# MIMXRT1015 register map
Vendor: nxp.com; File version: 1.0
CPU: CM7 r0p1, little endian, MPU, FPU, VTOR, 4 interrupt priority bits
Registers are 32-bit, read-write, reset 0x0 unless marked. A register's access mark holds for its fields unless they carry their own. Offsets are from the block's base; [hi:lo] are bit positions.

## IOMUXC (part 1 of 2)
Base 0x401F8000; register names take the prefix IOMUXC_
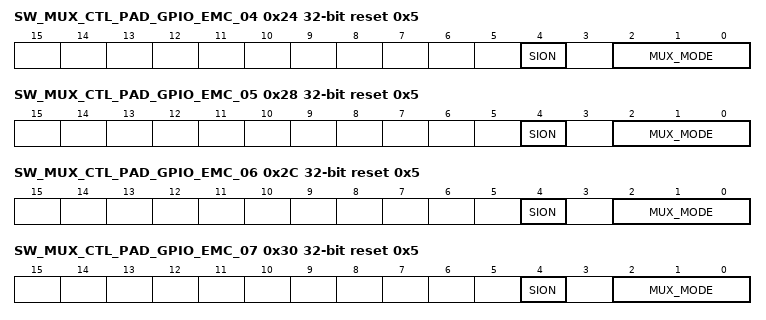
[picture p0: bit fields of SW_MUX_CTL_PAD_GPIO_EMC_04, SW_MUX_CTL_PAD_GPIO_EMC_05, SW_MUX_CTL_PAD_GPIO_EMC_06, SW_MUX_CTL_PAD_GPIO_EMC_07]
0x24 SW_MUX_CTL_PAD_GPIO_EMC_04 reset 0x5 — SW_MUX_CTL_PAD_GPIO_EMC_04 SW MUX Control Register
  [4] SION — Software Input On Field.
    0=DISABLED (Input Path is determined by functionality); 1=ENABLED (Force input path of pad GPIO_EMC_04)
  [2:0] MUX_MODE — MUX Mode Select Field.
    1=ALT1 (Select mux mode: ALT1 mux port: XBAR1_XBAR_INOUT04 of instance: xbar1); 2=ALT2 (Select mux mode: ALT2 mux port: SPDIF_OUT of instance: spdif); 3=ALT3 (Select mux mode: ALT3 mux port: SAI2_TX_BCLK of instance: sai2); 4=ALT4 (Select mux mode: ALT4 mux port: FLEXIO1_FLEXIO16 of instance: flexio1); 5=ALT5 (Select mux mode: ALT5 mux port: GPIO2_IO04 of instance: gpio2); 7=ALT7 (Select mux mode: ALT7 mux port: SJC_JTAG_ACT of instance: sjc)
0x28 SW_MUX_CTL_PAD_GPIO_EMC_05 reset 0x5 — SW_MUX_CTL_PAD_GPIO_EMC_05 SW MUX Control Register
  [4] SION — Software Input On Field.
    0=DISABLED (Input Path is determined by functionality); 1=ENABLED (Force input path of pad GPIO_EMC_05)
  [2:0] MUX_MODE — MUX Mode Select Field.
    1=ALT1 (Select mux mode: ALT1 mux port: XBAR1_XBAR_INOUT05 of instance: xbar1); 2=ALT2 (Select mux mode: ALT2 mux port: SPDIF_IN of instance: spdif); 3=ALT3 (Select mux mode: ALT3 mux port: SAI2_TX_SYNC of instance: sai2); 4=ALT4 (Select mux mode: ALT4 mux port: FLEXIO1_FLEXIO17 of instance: flexio1); 5=ALT5 (Select mux mode: ALT5 mux port: GPIO2_IO05 of instance: gpio2); 7=ALT7 (Select mux mode: ALT7 mux port: SJC_DE_B of instance: sjc)
0x2C SW_MUX_CTL_PAD_GPIO_EMC_06 reset 0x5 — SW_MUX_CTL_PAD_GPIO_EMC_06 SW MUX Control Register
  [4] SION — Software Input On Field.
    0=DISABLED (Input Path is determined by functionality); 1=ENABLED (Force input path of pad GPIO_EMC_06)
  [2:0] MUX_MODE — MUX Mode Select Field.
    1=ALT1 (Select mux mode: ALT1 mux port: XBAR1_XBAR_INOUT06 of instance: xbar1); 2=ALT2 (Select mux mode: ALT2 mux port: LPUART3_TX of instance: lpuart3); 3=ALT3 (Select mux mode: ALT3 mux port: SAI2_TX_DATA of instance: sai2); 4=ALT4 (Select mux mode: ALT4 mux port: FLEXIO1_FLEXIO18 of instance: flexio1); 5=ALT5 (Select mux mode: ALT5 mux port: GPIO2_IO06 of instance: gpio2)
0x30 SW_MUX_CTL_PAD_GPIO_EMC_07 reset 0x5 — SW_MUX_CTL_PAD_GPIO_EMC_07 SW MUX Control Register
  [4] SION — Software Input On Field.
    0=DISABLED (Input Path is determined by functionality); 1=ENABLED (Force input path of pad GPIO_EMC_07)
  [2:0] MUX_MODE — MUX Mode Select Field.
    1=ALT1 (Select mux mode: ALT1 mux port: XBAR1_XBAR_INOUT07 of instance: xbar1); 2=ALT2 (Select mux mode: ALT2 mux port: LPUART3_RX of instance: lpuart3); 3=ALT3 (Select mux mode: ALT3 mux port: SAI2_RX_SYNC of instance: sai2); 4=ALT4 (Select mux mode: ALT4 mux port: FLEXIO1_FLEXIO19 of instance: flexio1); 5=ALT5 (Select mux mode: ALT5 mux port: GPIO2_IO07 of instance: gpio2)
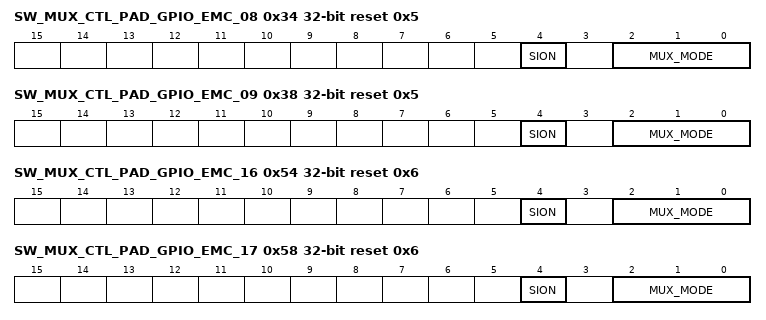
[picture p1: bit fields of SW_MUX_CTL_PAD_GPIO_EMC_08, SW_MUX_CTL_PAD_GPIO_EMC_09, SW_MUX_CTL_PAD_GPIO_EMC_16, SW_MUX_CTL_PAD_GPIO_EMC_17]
0x34 SW_MUX_CTL_PAD_GPIO_EMC_08 reset 0x5 — SW_MUX_CTL_PAD_GPIO_EMC_08 SW MUX Control Register
  [4] SION — Software Input On Field.
    0=DISABLED (Input Path is determined by functionality); 1=ENABLED (Force input path of pad GPIO_EMC_08)
  [2:0] MUX_MODE — MUX Mode Select Field.
    1=ALT1 (Select mux mode: ALT1 mux port: XBAR1_XBAR_INOUT08 of instance: xbar1); 3=ALT3 (Select mux mode: ALT3 mux port: SAI2_RX_DATA of instance: sai2); 4=ALT4 (Select mux mode: ALT4 mux port: FLEXIO1_FLEXIO20 of instance: flexio1); 5=ALT5 (Select mux mode: ALT5 mux port: GPIO2_IO08 of instance: gpio2)
0x38 SW_MUX_CTL_PAD_GPIO_EMC_09 reset 0x5 — SW_MUX_CTL_PAD_GPIO_EMC_09 SW MUX Control Register
  [4] SION — Software Input On Field.
    0=DISABLED (Input Path is determined by functionality); 1=ENABLED (Force input path of pad GPIO_EMC_09)
  [2:0] MUX_MODE — MUX Mode Select Field.
    1=ALT1 (Select mux mode: ALT1 mux port: XBAR1_XBAR_INOUT09 of instance: xbar1); 3=ALT3 (Select mux mode: ALT3 mux port: SAI2_RX_BCLK of instance: sai2); 4=ALT4 (Select mux mode: ALT4 mux port: FLEXIO1_FLEXIO21 of instance: flexio1); 5=ALT5 (Select mux mode: ALT5 mux port: GPIO2_IO09 of instance: gpio2)
0x54 SW_MUX_CTL_PAD_GPIO_EMC_16 reset 0x6 — SW_MUX_CTL_PAD_GPIO_EMC_16 SW MUX Control Register
  [4] SION — Software Input On Field.
    0=DISABLED (Input Path is determined by functionality); 1=ENABLED (Force input path of pad GPIO_EMC_16)
  [2:0] MUX_MODE — MUX Mode Select Field.
    2=ALT2 (Select mux mode: ALT2 mux port: MQS_RIGHT of instance: mqs); 3=ALT3 (Select mux mode: ALT3 mux port: SAI2_MCLK of instance: sai2); 5=ALT5 (Select mux mode: ALT5 mux port: GPIO2_IO16 of instance: gpio2); 6=ALT6 (Select mux mode: ALT6 mux port: SRC_BOOT_MODE00 of instance: src)
0x58 SW_MUX_CTL_PAD_GPIO_EMC_17 reset 0x6 — SW_MUX_CTL_PAD_GPIO_EMC_17 SW MUX Control Register
  [4] SION — Software Input On Field.
    0=DISABLED (Input Path is determined by functionality); 1=ENABLED (Force input path of pad GPIO_EMC_17)
  [2:0] MUX_MODE — MUX Mode Select Field.
    2=ALT2 (Select mux mode: ALT2 mux port: MQS_LEFT of instance: mqs); 3=ALT3 (Select mux mode: ALT3 mux port: SAI3_MCLK of instance: sai3); 5=ALT5 (Select mux mode: ALT5 mux port: GPIO2_IO17 of instance: gpio2); 6=ALT6 (Select mux mode: ALT6 mux port: SRC_BOOT_MODE01 of instance: src)
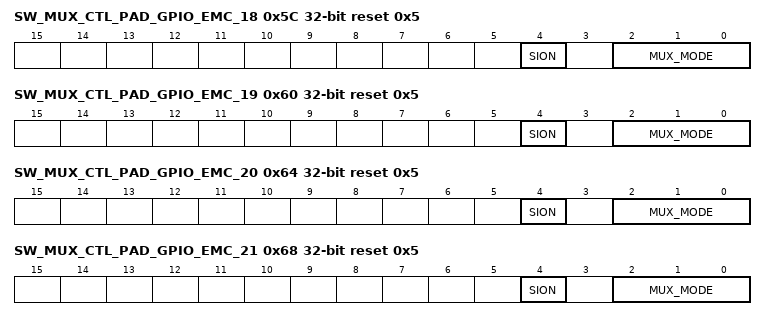
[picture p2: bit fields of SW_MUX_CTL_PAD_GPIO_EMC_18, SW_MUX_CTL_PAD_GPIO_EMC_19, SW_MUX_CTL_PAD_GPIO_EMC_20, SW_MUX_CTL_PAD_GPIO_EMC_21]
0x5C SW_MUX_CTL_PAD_GPIO_EMC_18 reset 0x5 — SW_MUX_CTL_PAD_GPIO_EMC_18 SW MUX Control Register
  [4] SION — Software Input On Field.
    0=DISABLED (Input Path is determined by functionality); 1=ENABLED (Force input path of pad GPIO_EMC_18)
  [2:0] MUX_MODE — MUX Mode Select Field.
    1=ALT1 (Select mux mode: ALT1 mux port: XBAR1_XBAR_INOUT16 of instance: xbar1); 2=ALT2 (Select mux mode: ALT2 mux port: LPI2C2_SDA of instance: lpi2c2); 3=ALT3 (Select mux mode: ALT3 mux port: SAI1_RX_SYNC of instance: sai1); 4=ALT4 (Select mux mode: ALT4 mux port: FLEXIO1_FLEXIO22 of instance: flexio1); 5=ALT5 (Select mux mode: ALT5 mux port: GPIO2_IO18 of instance: gpio2); 6=ALT6 (Select mux mode: ALT6 mux port: SRC_BT_CFG00 of instance: src)
0x60 SW_MUX_CTL_PAD_GPIO_EMC_19 reset 0x5 — SW_MUX_CTL_PAD_GPIO_EMC_19 SW MUX Control Register
  [4] SION — Software Input On Field.
    0=DISABLED (Input Path is determined by functionality); 1=ENABLED (Force input path of pad GPIO_EMC_19)
  [2:0] MUX_MODE — MUX Mode Select Field.
    1=ALT1 (Select mux mode: ALT1 mux port: XBAR1_XBAR_INOUT17 of instance: xbar1); 2=ALT2 (Select mux mode: ALT2 mux port: LPI2C2_SCL of instance: lpi2c2); 3=ALT3 (Select mux mode: ALT3 mux port: SAI1_RX_BCLK of instance: sai1); 4=ALT4 (Select mux mode: ALT4 mux port: FLEXIO1_FLEXIO23 of instance: flexio1); 5=ALT5 (Select mux mode: ALT5 mux port: GPIO2_IO19 of instance: gpio2); 6=ALT6 (Select mux mode: ALT6 mux port: SRC_BT_CFG01 of instance: src)
0x64 SW_MUX_CTL_PAD_GPIO_EMC_20 reset 0x5 — SW_MUX_CTL_PAD_GPIO_EMC_20 SW MUX Control Register
  [4] SION — Software Input On Field.
    0=DISABLED (Input Path is determined by functionality); 1=ENABLED (Force input path of pad GPIO_EMC_20)
  [2:0] MUX_MODE — MUX Mode Select Field.
    1=ALT1 (Select mux mode: ALT1 mux port: FLEXPWM1_PWMA03 of instance: flexpwm1); 2=ALT2 (Select mux mode: ALT2 mux port: LPUART2_CTS_B of instance: lpuart2); 3=ALT3 (Select mux mode: ALT3 mux port: SAI1_MCLK of instance: sai1); 4=ALT4 (Select mux mode: ALT4 mux port: FLEXIO1_FLEXIO24 of instance: flexio1); 5=ALT5 (Select mux mode: ALT5 mux port: GPIO2_IO20 of instance: gpio2); 6=ALT6 (Select mux mode: ALT6 mux port: SRC_BT_CFG02 of instance: src)
0x68 SW_MUX_CTL_PAD_GPIO_EMC_21 reset 0x5 — SW_MUX_CTL_PAD_GPIO_EMC_21 SW MUX Control Register
  [4] SION — Software Input On Field.
    0=DISABLED (Input Path is determined by functionality); 1=ENABLED (Force input path of pad GPIO_EMC_21)
  [2:0] MUX_MODE — MUX Mode Select Field.
    1=ALT1 (Select mux mode: ALT1 mux port: FLEXPWM1_PWMB03 of instance: flexpwm1); 2=ALT2 (Select mux mode: ALT2 mux port: LPUART2_RTS_B of instance: lpuart2); 3=ALT3 (Select mux mode: ALT3 mux port: SAI1_RX_DATA00 of instance: sai1); 4=ALT4 (Select mux mode: ALT4 mux port: FLEXIO1_FLEXIO25 of instance: flexio1); 5=ALT5 (Select mux mode: ALT5 mux port: GPIO2_IO21 of instance: gpio2); 6=ALT6 (Select mux mode: ALT6 mux port: SRC_BT_CFG03 of instance: src)
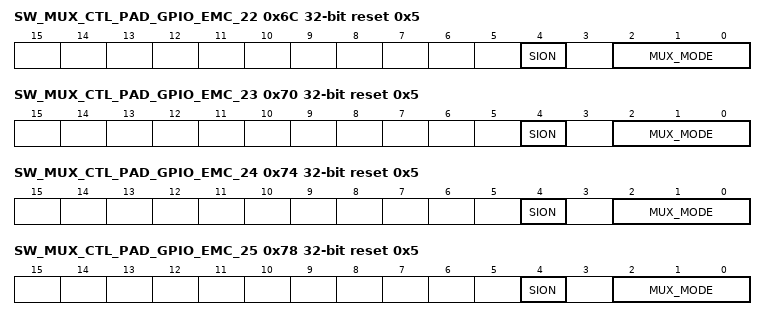
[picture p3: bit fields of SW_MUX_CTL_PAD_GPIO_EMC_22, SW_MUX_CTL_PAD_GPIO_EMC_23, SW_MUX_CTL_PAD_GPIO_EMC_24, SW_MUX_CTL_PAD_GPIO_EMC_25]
0x6C SW_MUX_CTL_PAD_GPIO_EMC_22 reset 0x5 — SW_MUX_CTL_PAD_GPIO_EMC_22 SW MUX Control Register
  [4] SION — Software Input On Field.
    0=DISABLED (Input Path is determined by functionality); 1=ENABLED (Force input path of pad GPIO_EMC_22)
  [2:0] MUX_MODE — MUX Mode Select Field.
    1=ALT1 (Select mux mode: ALT1 mux port: FLEXPWM1_PWMA02 of instance: flexpwm1); 2=ALT2 (Select mux mode: ALT2 mux port: LPUART2_TX of instance: lpuart2); 3=ALT3 (Select mux mode: ALT3 mux port: SAI1_TX_DATA03 of instance: sai1); 4=ALT4 (Select mux mode: ALT4 mux port: FLEXIO1_FLEXIO26 of instance: flexio1); 5=ALT5 (Select mux mode: ALT5 mux port: GPIO2_IO22 of instance: gpio2); 6=ALT6 (Select mux mode: ALT6 mux port: SRC_BT_CFG04 of instance: src)
0x70 SW_MUX_CTL_PAD_GPIO_EMC_23 reset 0x5 — SW_MUX_CTL_PAD_GPIO_EMC_23 SW MUX Control Register
  [4] SION — Software Input On Field.
    0=DISABLED (Input Path is determined by functionality); 1=ENABLED (Force input path of pad GPIO_EMC_23)
  [2:0] MUX_MODE — MUX Mode Select Field.
    1=ALT1 (Select mux mode: ALT1 mux port: FLEXPWM1_PWMB02 of instance: flexpwm1); 2=ALT2 (Select mux mode: ALT2 mux port: LPUART2_RX of instance: lpuart2); 3=ALT3 (Select mux mode: ALT3 mux port: SAI1_TX_DATA02 of instance: sai1); 4=ALT4 (Select mux mode: ALT4 mux port: FLEXIO1_FLEXIO27 of instance: flexio1); 5=ALT5 (Select mux mode: ALT5 mux port: GPIO2_IO23 of instance: gpio2); 6=ALT6 (Select mux mode: ALT6 mux port: SRC_BT_CFG05 of instance: src)
0x74 SW_MUX_CTL_PAD_GPIO_EMC_24 reset 0x5 — SW_MUX_CTL_PAD_GPIO_EMC_24 SW MUX Control Register
  [4] SION — Software Input On Field.
    0=DISABLED (Input Path is determined by functionality); 1=ENABLED (Force input path of pad GPIO_EMC_24)
  [2:0] MUX_MODE — MUX Mode Select Field.
    1=ALT1 (Select mux mode: ALT1 mux port: FLEXPWM1_PWMA01 of instance: flexpwm1); 3=ALT3 (Select mux mode: ALT3 mux port: SAI1_TX_DATA01 of instance: sai1); 4=ALT4 (Select mux mode: ALT4 mux port: FLEXIO1_FLEXIO28 of instance: flexio1); 5=ALT5 (Select mux mode: ALT5 mux port: GPIO2_IO24 of instance: gpio2); 6=ALT6 (Select mux mode: ALT6 mux port: SRC_BT_CFG06 of instance: src)
0x78 SW_MUX_CTL_PAD_GPIO_EMC_25 reset 0x5 — SW_MUX_CTL_PAD_GPIO_EMC_25 SW MUX Control Register
  [4] SION — Software Input On Field.
    0=DISABLED (Input Path is determined by functionality); 1=ENABLED (Force input path of pad GPIO_EMC_25)
  [2:0] MUX_MODE — MUX Mode Select Field.
    1=ALT1 (Select mux mode: ALT1 mux port: FLEXPWM1_PWMB01 of instance: flexpwm1); 3=ALT3 (Select mux mode: ALT3 mux port: SAI1_TX_DATA00 of instance: sai1); 4=ALT4 (Select mux mode: ALT4 mux port: FLEXIO1_FLEXIO29 of instance: flexio1); 5=ALT5 (Select mux mode: ALT5 mux port: GPIO2_IO25 of instance: gpio2); 6=ALT6 (Select mux mode: ALT6 mux port: SRC_BT_CFG07 of instance: src)
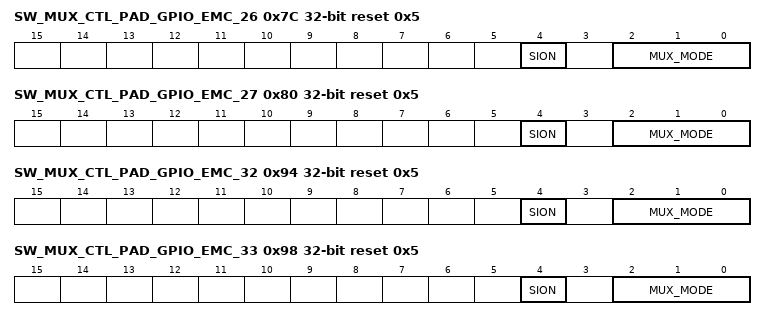
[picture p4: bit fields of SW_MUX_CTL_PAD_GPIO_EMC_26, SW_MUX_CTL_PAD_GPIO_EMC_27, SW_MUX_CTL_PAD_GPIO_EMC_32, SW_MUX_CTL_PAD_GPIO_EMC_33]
0x7C SW_MUX_CTL_PAD_GPIO_EMC_26 reset 0x5 — SW_MUX_CTL_PAD_GPIO_EMC_26 SW MUX Control Register
  [4] SION — Software Input On Field.
    0=DISABLED (Input Path is determined by functionality); 1=ENABLED (Force input path of pad GPIO_EMC_26)
  [2:0] MUX_MODE — MUX Mode Select Field.
    1=ALT1 (Select mux mode: ALT1 mux port: FLEXPWM1_PWMA00 of instance: flexpwm1); 3=ALT3 (Select mux mode: ALT3 mux port: SAI1_TX_BCLK of instance: sai1); 4=ALT4 (Select mux mode: ALT4 mux port: FLEXIO1_FLEXIO30 of instance: flexio1); 5=ALT5 (Select mux mode: ALT5 mux port: GPIO2_IO26 of instance: gpio2); 6=ALT6 (Select mux mode: ALT6 mux port: SRC_BT_CFG08 of instance: src)
0x80 SW_MUX_CTL_PAD_GPIO_EMC_27 reset 0x5 — SW_MUX_CTL_PAD_GPIO_EMC_27 SW MUX Control Register
  [4] SION — Software Input On Field.
    0=DISABLED (Input Path is determined by functionality); 1=ENABLED (Force input path of pad GPIO_EMC_27)
  [2:0] MUX_MODE — MUX Mode Select Field.
    1=ALT1 (Select mux mode: ALT1 mux port: FLEXPWM1_PWMB00 of instance: flexpwm1); 3=ALT3 (Select mux mode: ALT3 mux port: SAI1_TX_SYNC of instance: sai1); 4=ALT4 (Select mux mode: ALT4 mux port: FLEXIO1_FLEXIO31 of instance: flexio1); 5=ALT5 (Select mux mode: ALT5 mux port: GPIO2_IO27 of instance: gpio2); 6=ALT6 (Select mux mode: ALT6 mux port: SRC_BT_CFG09 of instance: src)
0x94 SW_MUX_CTL_PAD_GPIO_EMC_32 reset 0x5 — SW_MUX_CTL_PAD_GPIO_EMC_32 SW MUX Control Register
  [4] SION — Software Input On Field.
    0=DISABLED (Input Path is determined by functionality); 1=ENABLED (Force input path of pad GPIO_EMC_32)
  [2:0] MUX_MODE — MUX Mode Select Field.
    1=ALT1 (Select mux mode: ALT1 mux port: QTIMER1_TIMER0 of instance: qtimer1); 2=ALT2 (Select mux mode: ALT2 mux port: LPUART4_TX of instance: lpuart4); 3=ALT3 (Select mux mode: ALT3 mux port: SAI3_TX_DATA of instance: sai3); 5=ALT5 (Select mux mode: ALT5 mux port: GPIO3_IO00 of instance: gpio3); 7=ALT7 (Select mux mode: ALT7 mux port: REF_24M_OUT of instance: anatop)
0x98 SW_MUX_CTL_PAD_GPIO_EMC_33 reset 0x5 — SW_MUX_CTL_PAD_GPIO_EMC_33 SW MUX Control Register
  [4] SION — Software Input On Field.
    0=DISABLED (Input Path is determined by functionality); 1=ENABLED (Force input path of pad GPIO_EMC_33)
  [2:0] MUX_MODE — MUX Mode Select Field.
    1=ALT1 (Select mux mode: ALT1 mux port: QTIMER1_TIMER1 of instance: qtimer1); 2=ALT2 (Select mux mode: ALT2 mux port: LPUART4_RX of instance: lpuart4); 3=ALT3 (Select mux mode: ALT3 mux port: SAI3_TX_BCLK of instance: sai3); 5=ALT5 (Select mux mode: ALT5 mux port: GPIO3_IO01 of instance: gpio3)
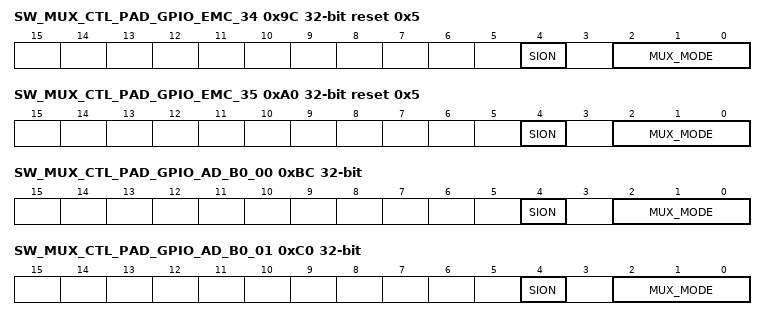
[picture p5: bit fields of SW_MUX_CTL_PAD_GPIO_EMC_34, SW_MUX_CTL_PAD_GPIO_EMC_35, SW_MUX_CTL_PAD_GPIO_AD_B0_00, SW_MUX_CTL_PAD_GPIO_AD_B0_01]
0x9C SW_MUX_CTL_PAD_GPIO_EMC_34 reset 0x5 — SW_MUX_CTL_PAD_GPIO_EMC_34 SW MUX Control Register
  [4] SION — Software Input On Field.
    0=DISABLED (Input Path is determined by functionality); 1=ENABLED (Force input path of pad GPIO_EMC_34)
  [2:0] MUX_MODE — MUX Mode Select Field.
    1=ALT1 (Select mux mode: ALT1 mux port: QTIMER1_TIMER2 of instance: qtimer1); 3=ALT3 (Select mux mode: ALT3 mux port: SAI3_TX_SYNC of instance: sai3); 5=ALT5 (Select mux mode: ALT5 mux port: GPIO3_IO02 of instance: gpio3)
0xA0 SW_MUX_CTL_PAD_GPIO_EMC_35 reset 0x5 — SW_MUX_CTL_PAD_GPIO_EMC_35 SW MUX Control Register
  [4] SION — Software Input On Field.
    0=DISABLED (Input Path is determined by functionality); 1=ENABLED (Force input path of pad GPIO_EMC_35)
  [2:0] MUX_MODE — MUX Mode Select Field.
    1=ALT1 (Select mux mode: ALT1 mux port: QTIMER1_TIMER3 of instance: qtimer1); 5=ALT5 (Select mux mode: ALT5 mux port: GPIO3_IO03 of instance: gpio3)
0xBC SW_MUX_CTL_PAD_GPIO_AD_B0_00 — SW_MUX_CTL_PAD_GPIO_AD_B0_00 SW MUX Control Register
  [4] SION — Software Input On Field.
    0=DISABLED (Input Path is determined by functionality); 1=ENABLED (Force input path of pad GPIO_AD_B0_00)
  [2:0] MUX_MODE — MUX Mode Select Field.
    0=ALT0 (Select mux mode: ALT0 mux port: JTAG_MUX_TMS of instance: jtag_mux); 5=ALT5 (Select mux mode: ALT5 mux port: GPIO1_IO00 of instance: gpio1); 7=ALT7 (Select mux mode: ALT7 mux port: GPT1_COMPARE1 of instance: gpt1)
0xC0 SW_MUX_CTL_PAD_GPIO_AD_B0_01 — SW_MUX_CTL_PAD_GPIO_AD_B0_01 SW MUX Control Register
  [4] SION — Software Input On Field.
    0=DISABLED (Input Path is determined by functionality); 1=ENABLED (Force input path of pad GPIO_AD_B0_01)
  [2:0] MUX_MODE — MUX Mode Select Field.
    0=ALT0 (Select mux mode: ALT0 mux port: JTAG_MUX_TCK of instance: jtag_mux); 5=ALT5 (Select mux mode: ALT5 mux port: GPIO1_IO01 of instance: gpio1); 7=ALT7 (Select mux mode: ALT7 mux port: GPT1_CAPTURE2 of instance: gpt1)
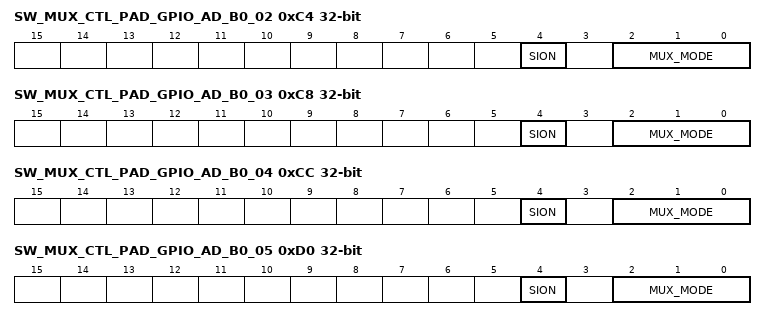
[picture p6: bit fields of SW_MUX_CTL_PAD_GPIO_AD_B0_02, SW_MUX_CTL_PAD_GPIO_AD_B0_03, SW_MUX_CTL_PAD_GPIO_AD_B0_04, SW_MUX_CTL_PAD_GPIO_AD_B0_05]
0xC4 SW_MUX_CTL_PAD_GPIO_AD_B0_02 — SW_MUX_CTL_PAD_GPIO_AD_B0_02 SW MUX Control Register
  [4] SION — Software Input On Field.
    0=DISABLED (Input Path is determined by functionality); 1=ENABLED (Force input path of pad GPIO_AD_B0_02)
  [2:0] MUX_MODE — MUX Mode Select Field.
    0=ALT0 (Select mux mode: ALT0 mux port: JTAG_MUX_MOD of instance: jtag_mux); 5=ALT5 (Select mux mode: ALT5 mux port: GPIO1_IO02 of instance: gpio1); 7=ALT7 (Select mux mode: ALT7 mux port: GPT1_CAPTURE1 of instance: gpt1)
0xC8 SW_MUX_CTL_PAD_GPIO_AD_B0_03 — SW_MUX_CTL_PAD_GPIO_AD_B0_03 SW MUX Control Register
  [4] SION — Software Input On Field.
    0=DISABLED (Input Path is determined by functionality); 1=ENABLED (Force input path of pad GPIO_AD_B0_03)
  [2:0] MUX_MODE — MUX Mode Select Field.
    0=ALT0 (Select mux mode: ALT0 mux port: JTAG_MUX_TDI of instance: jtag_mux); 2=ALT2 (Select mux mode: ALT2 mux port: WDOG1_WDOG_B of instance: wdog1); 3=ALT3 (Select mux mode: ALT3 mux port: SAI1_MCLK of instance: sai1); 5=ALT5 (Select mux mode: ALT5 mux port: GPIO1_IO03 of instance: gpio1); 6=ALT6 (Select mux mode: ALT6 mux port: USB_OTG1_OC of instance: usb); 7=ALT7 (Select mux mode: ALT7 mux port: CCM_PMIC_RDY of instance: ccm)
0xCC SW_MUX_CTL_PAD_GPIO_AD_B0_04 — SW_MUX_CTL_PAD_GPIO_AD_B0_04 SW MUX Control Register
  [4] SION — Software Input On Field.
    0=DISABLED (Input Path is determined by functionality); 1=ENABLED (Force input path of pad GPIO_AD_B0_04)
  [2:0] MUX_MODE — MUX Mode Select Field.
    0=ALT0 (Select mux mode: ALT0 mux port: JTAG_MUX_TDO of instance: jtag_mux); 5=ALT5 (Select mux mode: ALT5 mux port: GPIO1_IO04 of instance: gpio1); 6=ALT6 (Select mux mode: ALT6 mux port: USB_OTG1_PWR of instance: usb); 7=ALT7 (Select mux mode: ALT7 mux port: EWM_EWM_OUT_B of instance: ewm)
0xD0 SW_MUX_CTL_PAD_GPIO_AD_B0_05 — SW_MUX_CTL_PAD_GPIO_AD_B0_05 SW MUX Control Register
  [4] SION — Software Input On Field.
    0=DISABLED (Input Path is determined by functionality); 1=ENABLED (Force input path of pad GPIO_AD_B0_05)
  [2:0] MUX_MODE — MUX Mode Select Field.
    0=ALT0 (Select mux mode: ALT0 mux port: JTAG_MUX_TRSTB of instance: jtag_mux); 5=ALT5 (Select mux mode: ALT5 mux port: GPIO1_IO05 of instance: gpio1); 6=ALT6 (Select mux mode: ALT6 mux port: USB_OTG1_ID of instance: anatop); 7=ALT7 (Select mux mode: ALT7 mux port: NMI_GLUE_NMI of instance: nmi_glue)
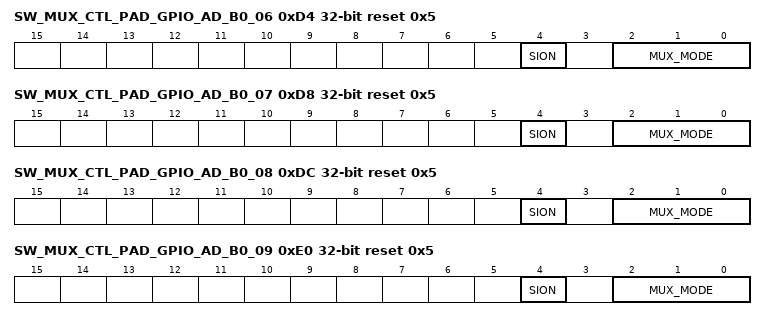
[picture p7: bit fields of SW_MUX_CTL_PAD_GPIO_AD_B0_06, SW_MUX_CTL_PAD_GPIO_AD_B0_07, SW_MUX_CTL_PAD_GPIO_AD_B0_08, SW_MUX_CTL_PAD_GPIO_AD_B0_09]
0xD4 SW_MUX_CTL_PAD_GPIO_AD_B0_06 reset 0x5 — SW_MUX_CTL_PAD_GPIO_AD_B0_06 SW MUX Control Register
  [4] SION — Software Input On Field.
    0=DISABLED (Input Path is determined by functionality); 1=ENABLED (Force input path of pad GPIO_AD_B0_06)
  [2:0] MUX_MODE — MUX Mode Select Field.
    0=ALT0 (Select mux mode: ALT0 mux port: PIT_TRIGGER00 of instance: pit); 1=ALT1 (Select mux mode: ALT1 mux port: MQS_RIGHT of instance: mqs); 2=ALT2 (Select mux mode: ALT2 mux port: LPUART1_TX of instance: lpuart1); 5=ALT5 (Select mux mode: ALT5 mux port: GPIO1_IO06 of instance: gpio1); 6=ALT6 (Select mux mode: ALT6 mux port: REF_32K_OUT of instance: anatop)
0xD8 SW_MUX_CTL_PAD_GPIO_AD_B0_07 reset 0x5 — SW_MUX_CTL_PAD_GPIO_AD_B0_07 SW MUX Control Register
  [4] SION — Software Input On Field.
    0=DISABLED (Input Path is determined by functionality); 1=ENABLED (Force input path of pad GPIO_AD_B0_07)
  [2:0] MUX_MODE — MUX Mode Select Field.
    0=ALT0 (Select mux mode: ALT0 mux port: PIT_TRIGGER01 of instance: pit); 1=ALT1 (Select mux mode: ALT1 mux port: MQS_LEFT of instance: mqs); 2=ALT2 (Select mux mode: ALT2 mux port: LPUART1_RX of instance: lpuart1); 5=ALT5 (Select mux mode: ALT5 mux port: GPIO1_IO07 of instance: gpio1); 6=ALT6 (Select mux mode: ALT6 mux port: REF_24M_OUT of instance: anatop)
0xDC SW_MUX_CTL_PAD_GPIO_AD_B0_08 reset 0x5 — SW_MUX_CTL_PAD_GPIO_AD_B0_08 SW MUX Control Register
  [4] SION — Software Input On Field.
    0=DISABLED (Input Path is determined by functionality); 1=ENABLED (Force input path of pad GPIO_AD_B0_08)
  [2:0] MUX_MODE — MUX Mode Select Field.
    2=ALT2 (Select mux mode: ALT2 mux port: LPUART1_CTS_B of instance: lpuart1); 3=ALT3 (Select mux mode: ALT3 mux port: KPP_COL00 of instance: kpp); 5=ALT5 (Select mux mode: ALT5 mux port: GPIO1_IO08 of instance: gpio1); 6=ALT6 (Select mux mode: ALT6 mux port: ARM_CM7_TXEV of instance: cm7_mxrt)
0xE0 SW_MUX_CTL_PAD_GPIO_AD_B0_09 reset 0x5 — SW_MUX_CTL_PAD_GPIO_AD_B0_09 SW MUX Control Register
  [4] SION — Software Input On Field.
    0=DISABLED (Input Path is determined by functionality); 1=ENABLED (Force input path of pad GPIO_AD_B0_09)
  [2:0] MUX_MODE — MUX Mode Select Field.
    2=ALT2 (Select mux mode: ALT2 mux port: LPUART1_RTS_B of instance: lpuart1); 3=ALT3 (Select mux mode: ALT3 mux port: KPP_ROW00 of instance: kpp); 4=ALT4 (Select mux mode: ALT4 mux port: CSU_CSU_INT_DEB of instance: csu); 5=ALT5 (Select mux mode: ALT5 mux port: GPIO1_IO09 of instance: gpio1); 6=ALT6 (Select mux mode: ALT6 mux port: ARM_CM7_RXEV of instance: cm7_mxrt)
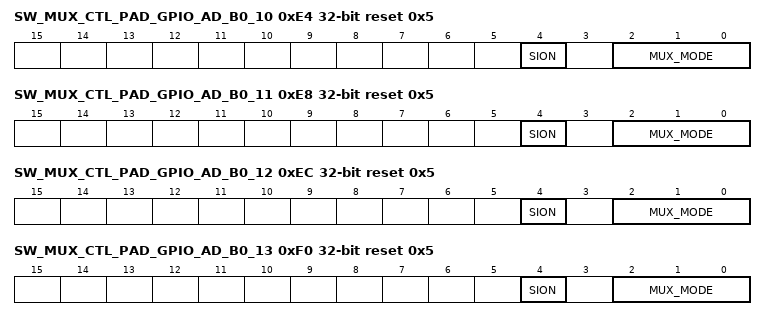
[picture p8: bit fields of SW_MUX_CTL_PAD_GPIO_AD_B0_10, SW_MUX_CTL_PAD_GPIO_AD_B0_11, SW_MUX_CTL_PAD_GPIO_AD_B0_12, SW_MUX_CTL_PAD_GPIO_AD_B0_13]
0xE4 SW_MUX_CTL_PAD_GPIO_AD_B0_10 reset 0x5 — SW_MUX_CTL_PAD_GPIO_AD_B0_10 SW MUX Control Register
  [4] SION — Software Input On Field.
    0=DISABLED (Input Path is determined by functionality); 1=ENABLED (Force input path of pad GPIO_AD_B0_10)
  [2:0] MUX_MODE — MUX Mode Select Field.
    1=ALT1 (Select mux mode: ALT1 mux port: LPSPI1_SCK of instance: lpspi1); 3=ALT3 (Select mux mode: ALT3 mux port: KPP_COL01 of instance: kpp); 5=ALT5 (Select mux mode: ALT5 mux port: GPIO1_IO10 of instance: gpio1); 6=ALT6 (Select mux mode: ALT6 mux port: ARM_CM7_TRACE_CLK of instance: cm7_mxrt)
0xE8 SW_MUX_CTL_PAD_GPIO_AD_B0_11 reset 0x5 — SW_MUX_CTL_PAD_GPIO_AD_B0_11 SW MUX Control Register
  [4] SION — Software Input On Field.
    0=DISABLED (Input Path is determined by functionality); 1=ENABLED (Force input path of pad GPIO_AD_B0_11)
  [2:0] MUX_MODE — MUX Mode Select Field.
    1=ALT1 (Select mux mode: ALT1 mux port: LPSPI1_PCS0 of instance: lpspi1); 3=ALT3 (Select mux mode: ALT3 mux port: KPP_ROW01 of instance: kpp); 5=ALT5 (Select mux mode: ALT5 mux port: GPIO1_IO11 of instance: gpio1); 6=ALT6 (Select mux mode: ALT6 mux port: ARM_CM7_TRACE_SWO of instance: cm7_mxrt)
0xEC SW_MUX_CTL_PAD_GPIO_AD_B0_12 reset 0x5 — SW_MUX_CTL_PAD_GPIO_AD_B0_12 SW MUX Control Register
  [4] SION — Software Input On Field.
    0=DISABLED (Input Path is determined by functionality); 1=ENABLED (Force input path of pad GPIO_AD_B0_12)
  [2:0] MUX_MODE — MUX Mode Select Field.
    1=ALT1 (Select mux mode: ALT1 mux port: LPSPI1_SDO of instance: lpspi1); 2=ALT2 (Select mux mode: ALT2 mux port: LPUART3_CTS_B of instance: lpuart3); 3=ALT3 (Select mux mode: ALT3 mux port: KPP_COL02 of instance: kpp); 5=ALT5 (Select mux mode: ALT5 mux port: GPIO1_IO12 of instance: gpio1); 6=ALT6 (Select mux mode: ALT6 mux port: ARM_CM7_TRACE00 of instance: cm7_mxrt); 7=ALT7 (Select mux mode: ALT7 mux port: SNVS_HP_VIO_5_CTL of instance: snvs_hp)
0xF0 SW_MUX_CTL_PAD_GPIO_AD_B0_13 reset 0x5 — SW_MUX_CTL_PAD_GPIO_AD_B0_13 SW MUX Control Register
  [4] SION — Software Input On Field.
    0=DISABLED (Input Path is determined by functionality); 1=ENABLED (Force input path of pad GPIO_AD_B0_13)
  [2:0] MUX_MODE — MUX Mode Select Field.
    1=ALT1 (Select mux mode: ALT1 mux port: LPSPI1_SDI of instance: lpspi1); 2=ALT2 (Select mux mode: ALT2 mux port: LPUART3_RTS_B of instance: lpuart3); 3=ALT3 (Select mux mode: ALT3 mux port: KPP_ROW02 of instance: kpp); 5=ALT5 (Select mux mode: ALT5 mux port: GPIO1_IO13 of instance: gpio1); 6=ALT6 (Select mux mode: ALT6 mux port: ARM_CM7_TRACE01 of instance: cm7_mxrt); 7=ALT7 (Select mux mode: ALT7 mux port: SNVS_HP_VIO_5_B of instance: snvs_hp)
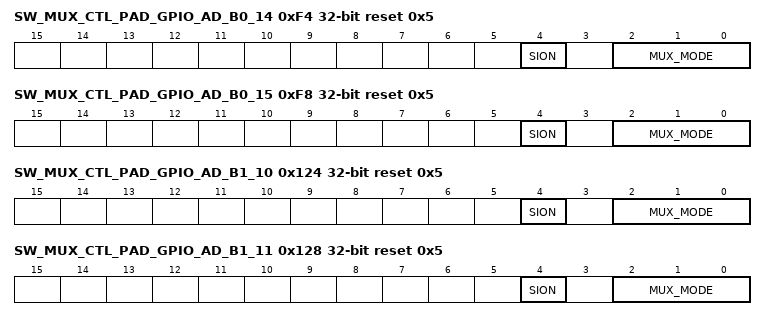
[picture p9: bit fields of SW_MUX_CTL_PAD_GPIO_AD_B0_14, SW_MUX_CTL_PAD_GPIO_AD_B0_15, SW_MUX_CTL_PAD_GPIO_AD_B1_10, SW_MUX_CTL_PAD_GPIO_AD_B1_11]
0xF4 SW_MUX_CTL_PAD_GPIO_AD_B0_14 reset 0x5 — SW_MUX_CTL_PAD_GPIO_AD_B0_14 SW MUX Control Register
  [4] SION — Software Input On Field.
    0=DISABLED (Input Path is determined by functionality); 1=ENABLED (Force input path of pad GPIO_AD_B0_14)
  [2:0] MUX_MODE — MUX Mode Select Field.
    2=ALT2 (Select mux mode: ALT2 mux port: LPUART3_TX of instance: lpuart3); 3=ALT3 (Select mux mode: ALT3 mux port: KPP_COL03 of instance: kpp); 5=ALT5 (Select mux mode: ALT5 mux port: GPIO1_IO14 of instance: gpio1); 6=ALT6 (Select mux mode: ALT6 mux port: ARM_CM7_TRACE02 of instance: cm7_mxrt); 7=ALT7 (Select mux mode: ALT7 mux port: WDOG1_WDOG_ANY of instance: wdog1)
0xF8 SW_MUX_CTL_PAD_GPIO_AD_B0_15 reset 0x5 — SW_MUX_CTL_PAD_GPIO_AD_B0_15 SW MUX Control Register
  [4] SION — Software Input On Field.
    0=DISABLED (Input Path is determined by functionality); 1=ENABLED (Force input path of pad GPIO_AD_B0_15)
  [2:0] MUX_MODE — MUX Mode Select Field.
    2=ALT2 (Select mux mode: ALT2 mux port: LPUART3_RX of instance: lpuart3); 3=ALT3 (Select mux mode: ALT3 mux port: KPP_ROW03 of instance: kpp); 5=ALT5 (Select mux mode: ALT5 mux port: GPIO1_IO15 of instance: gpio1); 6=ALT6 (Select mux mode: ALT6 mux port: ARM_CM7_TRACE03 of instance: cm7_mxrt)
0x124 SW_MUX_CTL_PAD_GPIO_AD_B1_10 reset 0x5 — SW_MUX_CTL_PAD_GPIO_AD_B1_10 SW MUX Control Register
  [4] SION — Software Input On Field.
    0=DISABLED (Input Path is determined by functionality); 1=ENABLED (Force input path of pad GPIO_AD_B1_10)
  [2:0] MUX_MODE — MUX Mode Select Field.
    0=ALT0 (Select mux mode: ALT0 mux port: USB_OTG1_PWR of instance: usb); 1=ALT1 (Select mux mode: ALT1 mux port: FLEXPWM1_PWMA02 of instance: flexpwm1); 2=ALT2 (Select mux mode: ALT2 mux port: LPUART4_TX of instance: lpuart4); 4=ALT4 (Select mux mode: ALT4 mux port: FLEXIO1_FLEXIO05 of instance: flexio1); 5=ALT5 (Select mux mode: ALT5 mux port: GPIO1_IO26 of instance: gpio1); 6=ALT6 (Select mux mode: ALT6 mux port: GPT2_CAPTURE1 of instance: gpt2)
0x128 SW_MUX_CTL_PAD_GPIO_AD_B1_11 reset 0x5 — SW_MUX_CTL_PAD_GPIO_AD_B1_11 SW MUX Control Register
  [4] SION — Software Input On Field.
    0=DISABLED (Input Path is determined by functionality); 1=ENABLED (Force input path of pad GPIO_AD_B1_11)
  [2:0] MUX_MODE — MUX Mode Select Field.
    0=ALT0 (Select mux mode: ALT0 mux port: USB_OTG1_ID of instance: anatop); 1=ALT1 (Select mux mode: ALT1 mux port: FLEXPWM1_PWMB02 of instance: flexpwm1); 2=ALT2 (Select mux mode: ALT2 mux port: LPUART4_RX of instance: lpuart4); 4=ALT4 (Select mux mode: ALT4 mux port: FLEXIO1_FLEXIO04 of instance: flexio1); 5=ALT5 (Select mux mode: ALT5 mux port: GPIO1_IO27 of instance: gpio1); 6=ALT6 (Select mux mode: ALT6 mux port: GPT2_COMPARE1 of instance: gpt2)
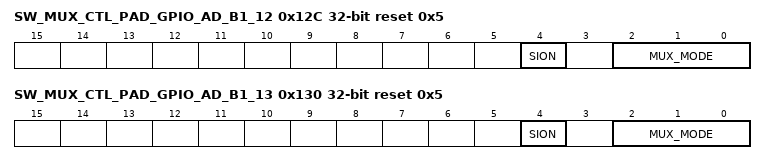
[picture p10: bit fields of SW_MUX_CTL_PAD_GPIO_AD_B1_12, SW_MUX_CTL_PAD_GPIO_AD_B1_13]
0x12C SW_MUX_CTL_PAD_GPIO_AD_B1_12 reset 0x5 — SW_MUX_CTL_PAD_GPIO_AD_B1_12 SW MUX Control Register
  [4] SION — Software Input On Field.
    0=DISABLED (Input Path is determined by functionality); 1=ENABLED (Force input path of pad GPIO_AD_B1_12)
  [2:0] MUX_MODE — MUX Mode Select Field.
    0=ALT0 (Select mux mode: ALT0 mux port: USB_OTG1_OC of instance: usb); 1=ALT1 (Select mux mode: ALT1 mux port: ACMP_OUT00 of instance: acmp); 4=ALT4 (Select mux mode: ALT4 mux port: FLEXIO1_FLEXIO03 of instance: flexio1); 5=ALT5 (Select mux mode: ALT5 mux port: GPIO1_IO28 of instance: gpio1); 6=ALT6 (Select mux mode: ALT6 mux port: FLEXPWM1_PWMA03 of instance: flexpwm1)
0x130 SW_MUX_CTL_PAD_GPIO_AD_B1_13 reset 0x5 — SW_MUX_CTL_PAD_GPIO_AD_B1_13 SW MUX Control Register
  [4] SION — Software Input On Field.
    0=DISABLED (Input Path is determined by functionality); 1=ENABLED (Force input path of pad GPIO_AD_B1_13)
  [2:0] MUX_MODE — MUX Mode Select Field.
    0=ALT0 (Select mux mode: ALT0 mux port: LPI2C1_HREQ of instance: lpi2c1); 1=ALT1 (Select mux mode: ALT1 mux port: ACMP_OUT01 of instance: acmp); 4=ALT4 (Select mux mode: ALT4 mux port: FLEXIO1_FLEXIO02 of instance: flexio1); 5=ALT5 (Select mux mode: ALT5 mux port: GPIO1_IO29 of instance: gpio1); 6=ALT6 (Select mux mode: ALT6 mux port: FLEXPWM1_PWMB03 of instance: flexpwm1)
